# ATtiny841 device description
Architecture: AVR8; Family: tinyAVR
Registers are 8-bit, access not given, no defined reset value unless marked. A register's access mark holds for its fields unless they carry their own. Offsets are from the block's base; [hi:lo] are bit positions; 'fields as' and 'values as' point back to an identical list.

## TWI — Two Wire Serial Interface
Instances: TWI 0x00
0xA0 TWSD — TWI Slave Data Register
  [7:0] TWSD — TWI slave data bit
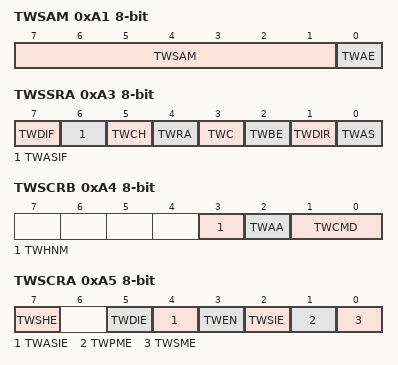
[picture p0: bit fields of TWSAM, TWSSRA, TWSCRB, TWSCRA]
0xA1 TWSAM — TWI Slave Address Mask Register
  [7:1] TWSAM (bit 1 of the value upward) — TWI Address Mask Bits
  [0] TWAE — TWI Address Enable
0xA2 TWSA — TWI Slave Address Register
0xA3 TWSSRA — TWI Slave Status Register A
  [7] TWDIF — TWI Data Interrupt Flag.
  [6] TWASIF — TWI Address/Stop Interrupt Flag
  [5] TWCH — TWI Clock Hold
  [4] TWRA — TWI Receive Acknowledge
  [3] TWC — TWI Collision
  [2] TWBE — TWI Bus Error
  [1] TWDIR — TWI Read/Write Direction
  [0] TWAS — TWI Address or Stop
0xA4 TWSCRB — TWI Slave Control Register B
  [3] TWHNM — TWI High Noise Mode
  [2] TWAA — TWI Acknowledge Action
  [1:0] TWCMD
0xA5 TWSCRA — TWI Slave Control Register A
  [7] TWSHE — TWI SDA Hold Time Enable
  [5] TWDIE — TWI Data Interrupt Enable
  [4] TWASIE — TWI Address/Stop Interrupt Enable
  [3] TWEN — Two-Wire Interface Enable
  [2] TWSIE — TWI Stop Interrupt Enable
  [1] TWPME — TWI Promiscuous Mode Enable
  [0] TWSME — TWI Smart Mode Enable

## ADC — Analog-to-Digital Converter
Instances: ADC 0x00
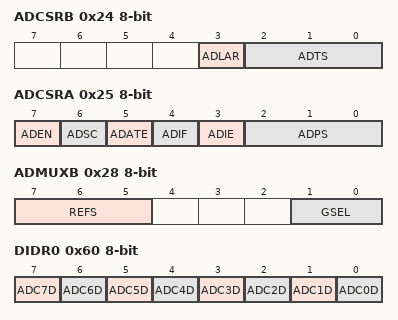
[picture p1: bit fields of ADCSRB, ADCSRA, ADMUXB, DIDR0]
0x24 ADCSRB — ADC Control and Status Register B
  [3] ADLAR
  [2:0] ADTS — ADC Auto Trigger Sources
    0=FREE_RUNNING_MODE; 1=ANALOG_COMPARATOR_0; 2=EXTERNAL_INTERRUPT_REQUEST_0; 3=TIMER_COUNTER0_COMPARE_MATCH_A; 4=TIMER_COUNTER0_OVERFLOW; 5=TIMER_COUNTER1_COMPARE_MATCH_A; 6=TIMER_COUNTER1_OVERFLOW; 7=TIMER_COUNTER1_CAPTURE_EVENT
0x25 ADCSRA — The ADC Control and Status register
  [7] ADEN — ADC Enable
  [6] ADSC — ADC Start Conversion
  [5] ADATE — ADC Auto Trigger Enable
  [4] ADIF — ADC Interrupt Flag
  [3] ADIE — ADC Interrupt Enable
  [2:0] ADPS — ADC Prescaler Select Bits
    0=2; 1=2; 2=4; 3=8; 4=16; 5=32; 6=64; 7=128
0x26 ADC 16-bit — ADC Data Register Bytes
0x28 ADMUXB — The ADC multiplexer Selection Register B
  [7:5] REFS — Reference Selection Bits
  [1:0] GSEL — Gain Selection Bits
0x29 ADMUXA — The ADC multiplexer Selection Register A
  [5:0] MUX — Analog Channel and Gain Selection Bits
0x60 DIDR0 — Digital Input Disable Register 0
  [7] ADC7D — ADC7 Digital input Disable
  [6] ADC6D — ADC6 Digital input Disable
  [5] ADC5D — ADC5 Digital input Disable
  [4] ADC4D — ADC4/AIN11 Digital input Disable
  [3] ADC3D — ADC3/AIN10 Digital Input Disable
  [2] ADC2D — ADC2/AIN01 Digital input Disable
  [1] ADC1D — ADC1/AIN00 Digital input Disable
  [0] ADC0D — ADC0/AREF Digital input Disable
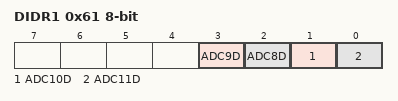
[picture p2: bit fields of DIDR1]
0x61 DIDR1 — Digital Input Disable Register 1
  [3] ADC9D — ADC9 Digital Input Disable
  [2] ADC8D — ADC8 Digital input Disable
  [1] ADC10D — ADC10 Digital input Disable
  [0] ADC11D — ADC11 Digital input Disable

## AC — Analog Comparator
Instances: AC 0x00
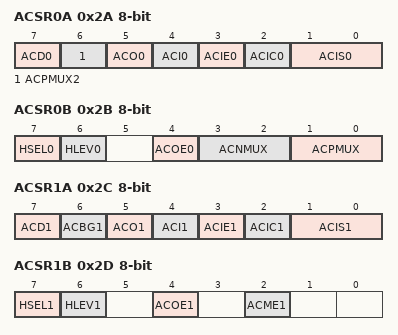
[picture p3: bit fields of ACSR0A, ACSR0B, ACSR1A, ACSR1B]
0x2A ACSR0A — Analog Comparator 0 Control And Status Register A
  [7] ACD0 — Analog Comparator 0 Disable
  [6] ACPMUX2 — Analog Comparator 0 Positive Input Multiplexer Bit 2
  [5] ACO0 — Analog Comparator 0 Output
  [4] ACI0 — Analog Comparator 0 Interrupt Flag
  [3] ACIE0 — Analog Comparator 0 Interrupt Enable
  [2] ACIC0 — Analog Comparator 0 Input Capture Enable
  [1:0] ACIS0 — Analog Comparator 0 Interrupt Mode Select bits
    0=INTERRUPT_ON_TOGGLE; 2=INTERRUPT_ON_FALLING_EDGE; 3=INTERRUPT_ON_RISING_EDGE
0x2B ACSR0B — Analog Comparator 0 Control And Status Register B
  [7] HSEL0 — Analog Comparator 0 Hysteresis Select
  [6] HLEV0 — Analog Comparator 0 Hysteresis Level
  [4] ACOE0 — Analog Comparator 0 Output Pin Enable
  [3:2] ACNMUX — Analog Comparator 0 Negative Input Multiplexer
  [1:0] ACPMUX — Analog Comparator 0 Positive Input Multiplexer Bits 1:0
0x2C ACSR1A — Analog Comparator 1 Control And Status Register A
  [7] ACD1 — Analog Comparator 1 Disable
  [6] ACBG1 — Analog Comparator 1 Bandgap Select
  [5] ACO1 — Analog Comparator 1 Output
  [4] ACI1 — Analog Comparator 1 Interrupt Flag
  [3] ACIE1 — Analog Comparator 1 Interrupt Enable
  [2] ACIC1 — Analog Comparator 1 Input Capture Enable
  [1:0] ACIS1 — Analog Comparator 1 Interrupt Mode Select bits
    values as ACSR0A.ACIS0
0x2D ACSR1B — Analog Comparator 1 Control And Status Register B
  [7] HSEL1 — Analog Comparator 1 Hysteresis Select
  [6] HLEV1 — Analog Comparator 1 Hysteresis Level
  [4] ACOE1 — Analog Comparator 1 Output Pin Enable
  [2] ACME1 — Analog Comparator 1 Multiplexer Enable
